# STM32F765BGT6 register map
File version: 1.0
Registers are 32-bit, access not given, reset 0x0 unless marked. A register's access mark holds for its fields unless they carry their own. Offsets are from the block's base; [hi:lo] are bit positions; {n}, {i} and the like mark numbered series; 'fields as' and 'values as' point back to an identical list.

## JPEG
Base 0x50051000
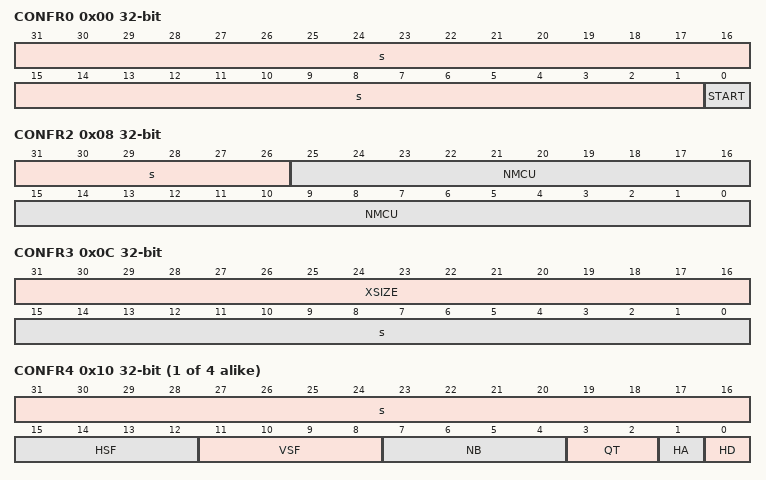
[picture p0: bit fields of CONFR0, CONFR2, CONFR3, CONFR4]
0x00 CONFR0
  [31:1] s, [0] START
0x04 CONFR1
  [31:16] YSIZE, [8] HDR, [7:6] NS, [5:4] COLSPACE, [3] DE, [15:2] s, [1:0] NF
0x08 CONFR2
  [31:26] s, [25:0] NMCU
0x0C CONFR3
  [31:16] XSIZE, [15:0] s
{0x0+4i} CONFR{i} (i=4..7)
  [31:16] s, [15:12] HSF, [11:8] VSF, [7:4] NB, [3:2] QT, [1] HA, [0] HD
0x30 CR
  [14] OFF, [13] IFF, [12] ODMAEN, [11] IDMAEN, [31:6] s, [5] EOCIE, [4] OFNEIE, [3] OFTIE, [2] IFNFIE, [1] IFTIE, [0] JCEN
0x34 SR
  [7] COF, [6] HPDF, [5] EOCF, [4] OFNEF, [3] OFTF, [2] IFNFF, [1] IFTF, [31:0] s
0x38 CFR
  [6] CHPDF, [5] CEOCF, [31:0] s
0x40 DIR
  [31:0] DATAIN
0x44 DOR
  [31:0] DATAOUT

## CRYP
Base 0x50060000
0x00 CR
  [17:16] GCM_CCMPH, [15] CRYPEN, [14] FFLUSH, [9:8] KEYSIZE, [7:6] DATATYPE, [19:3] ALGOMODE, [2] ALGODIR, [31:0] s
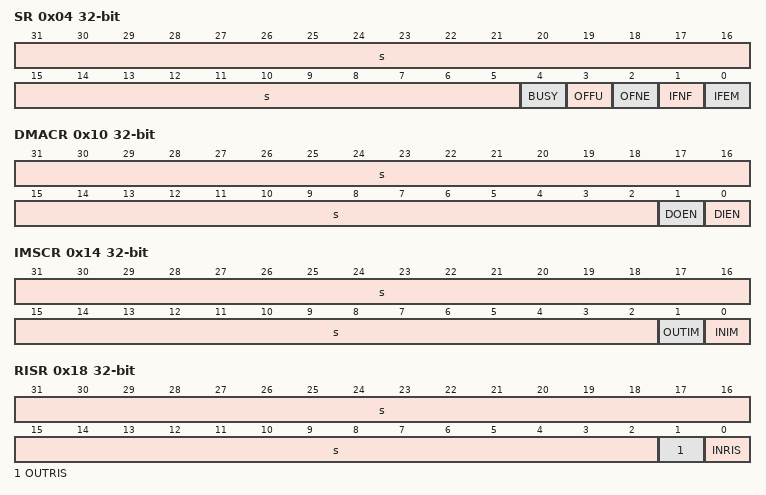
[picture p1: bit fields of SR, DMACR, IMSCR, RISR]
0x04 SR
  [31:5] s, [4] BUSY, [3] OFFU, [2] OFNE, [1] IFNF, [0] IFEM
0x08 DIN
  [31:0] DATAIN
0x0C DOUT
  [31:0] DATAOUT
0x10 DMACR
  [31:2] s, [1] DOEN, [0] DIEN
0x14 IMSCR
  [31:2] s, [1] OUTIM, [0] INIM
0x18 RISR
  [31:2] s, [1] OUTRIS, [0] INRIS
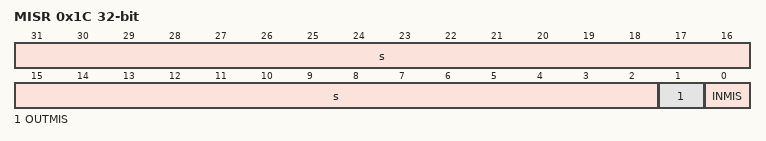
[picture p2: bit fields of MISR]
0x1C MISR
  [31:2] s, [1] OUTMIS, [0] INMIS
0x20 K0LR
  [31:0] CRYP_K0LR
0x24 K0RR
  [31:0] CRYP_K0RR
0x38 K3LR
  [31:0] CRYP_K3LR
0x3C K3RR
  [31:0] CRYP_K3RR
0x40 IV0LR
  [31:0] CRYP_IV0LR
0x44 IV0RR
  [31:0] CRYP_IV0RR
0x48 IV1LR
  [31:0] CRYP_IV1LR
0x4C IV1RR
  [31:0] CRYP_IV1RR

## HASH
Base 0x50060400
0x00 CR
  [16] LKEY, [13] MDMAT, [12] DINNE, [11:8] NBW, [18:7] ALGO, [6] MODE, [5:4] DATATYPE, [3] DMAE, [2] INIT, [31:0] s
0x04 DIN
  [31:0] DATAIN
0x08 STR
  [8] DCAL, [31:5] s, [4:0] NBLW
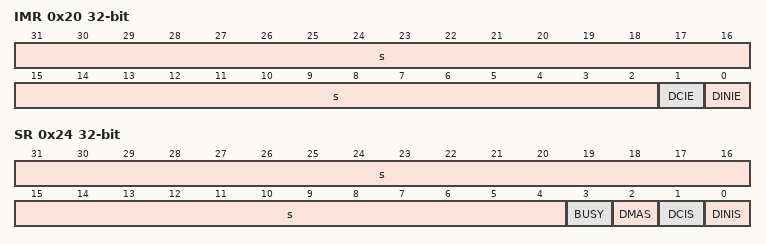
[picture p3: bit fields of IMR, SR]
0x20 IMR
  [31:2] s, [1] DCIE, [0] DINIE
0x24 SR
  [31:4] s, [3] BUSY, [2] DMAS, [1] DCIS, [0] DINIS
0xF8 CSR0
0xFC CSR1
0x1CC CSR53
{0x310+4i} HR{i} (i=0..7)
  [31:0] H{i}

## RNG
Base 0x50060800
0x00 CR
  [5] CED, [3] IE, [2] RNGEN, [31:0] s
0x04 SR
  [6] SEIS, [5] CEIS, [31:3] s, [2] SECS, [1] CECS, [0] DRDY
0x08 DR
  [31:0] RNDATA

## FMC
Base 0xA0000000
0x00 BCR1
  [21] WFDIS, [20] CCLKEN, [19] CBURSTRW, [18:16] CPSIZE, [15] ASYNCWAIT, [14] EXTMOD, [13] WAITEN, [12] WREN, [11] WAITCFG, [9] WAITPOL, [8] BURSTEN, [31:7] s, [6] FACCEN, [5:4] MWID, [3:2] MTYP, [1] MUXEN, [0] MBKEN
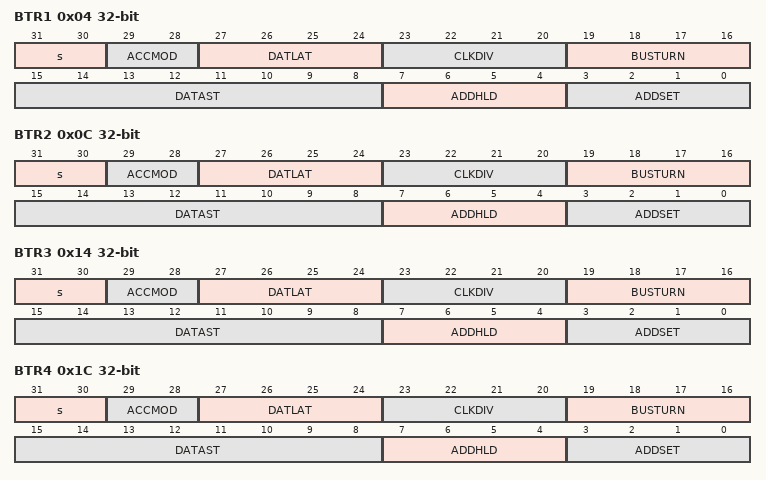
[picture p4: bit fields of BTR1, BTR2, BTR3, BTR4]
0x04 BTR1
  [31:30] s, [29:28] ACCMOD, [27:24] DATLAT, [23:20] CLKDIV, [19:16] BUSTURN, [15:8] DATAST, [7:4] ADDHLD, [3:0] ADDSET
0x08 BCR2
  [19] CBURSTRW, [18:16] CPSIZE, [15] ASYNCWAIT, [14] EXTMOD, [13] WAITEN, [12] WREN, [11] WAITCFG, [9] WAITPOL, [8] BURSTEN, [31:7] s, [6] FACCEN, [5:4] MWID, [3:2] MTYP, [1] MUXEN, [0] MBKEN
0x0C BTR2
  fields as BTR1
0x10 BCR3
  fields as BCR2
0x14 BTR3
  fields as BTR1
0x18 BCR4
  fields as BCR2
0x1C BTR4
  fields as BTR1
0x80 PCR
  [19:17] ECCPS, [16:13] TAR, [12:9] TCLR, [6] ECCEN, [5:4] PWID, [3] PTYP, [2] PBKEN, [1] PWAITEN, [31:0] s
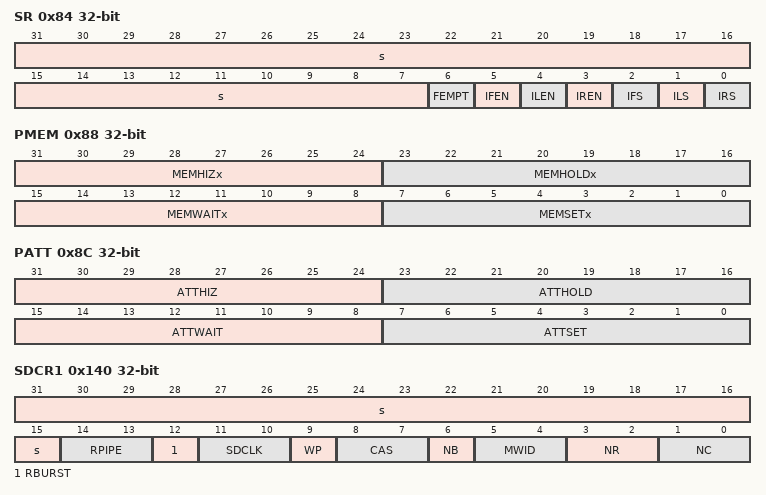
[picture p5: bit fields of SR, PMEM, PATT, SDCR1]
0x84 SR
  [31:7] s, [6] FEMPT, [5] IFEN, [4] ILEN, [3] IREN, [2] IFS, [1] ILS, [0] IRS
0x88 PMEM
  [31:24] MEMHIZx, [23:16] MEMHOLDx, [15:8] MEMWAITx, [7:0] MEMSETx
0x8C PATT
  [31:24] ATTHIZ, [23:16] ATTHOLD, [15:8] ATTWAIT, [7:0] ATTSET
0x94 ECCR
  [31:0] ECCx
{0xFC+8i} BWTR{i} (i=1..4)
  [29:28] ACCMOD, [31:20] s, [19:16] BUSTURN, [15:8] DATAST, [7:4] ADDHLD, [3:0] ADDSET
0x140 SDCR1
  [31:15] s, [14:13] RPIPE, [12] RBURST, [11:10] SDCLK, [9] WP, [8:7] CAS, [6] NB, [5:4] MWID, [3:2] NR, [1:0] NC
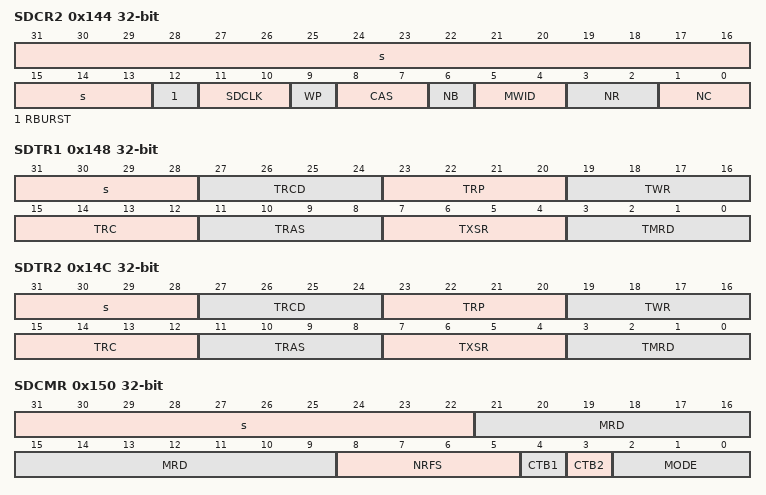
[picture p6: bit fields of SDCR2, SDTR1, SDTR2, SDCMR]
0x144 SDCR2
  [31:13] s, [12] RBURST, [11:10] SDCLK, [9] WP, [8:7] CAS, [6] NB, [5:4] MWID, [3:2] NR, [1:0] NC
0x148 SDTR1
  [31:28] s, [27:24] TRCD, [23:20] TRP, [19:16] TWR, [15:12] TRC, [11:8] TRAS, [7:4] TXSR, [3:0] TMRD
0x14C SDTR2
  fields as SDTR1
0x150 SDCMR
  [31:22] s, [21:9] MRD, [8:5] NRFS, [4] CTB1, [3] CTB2, [2:0] MODE
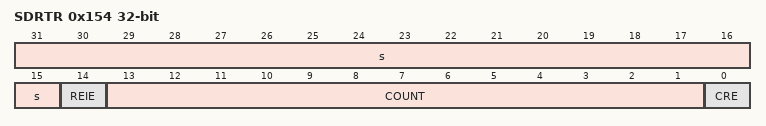
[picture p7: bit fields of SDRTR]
0x154 SDRTR
  [31:15] s, [14] REIE, [13:1] COUNT, [0] CRE
0x158 SDSR
  [5] BUSY, [4:3] MODES2, [2:1] MODES1, [31:0] s

## QUADSPICR
Base 0xA0001000
0x00 CR
  [31:24] PRESCALER, [23] PMM, [22] APMS, [20] TOIE, [19] SMIE, [18] FTIE, [17] TCIE, [16] TEIE, [12:8] FTHRES, [7] FSEL, [6] DFM, [21:5] s, [4] SSHIFT, [3] TCEN, [2] DMAEN, [1] ABORT, [0] EN
0x04 DCR
  [20:16] FSIZE, [10:8] CSHT, [31:1] s, [0] CKMODE
0x08 SR
  [14:8] FLEVEL, [31:6] s, [5] BUS, [4] TOF, [3] SMF, [2] FTF, [1] TCF, [0] TEF
0x0C FCR
  [4] CTOF, [3] CSMF, [31:2] s, [1] CTCF, [0] CTEF
0x10 DLR
  [31:0] DL
0x14 CCR
  [31] DDRM, [30] DHHC, [28] SIOO, [27:26] FMODE, [25:24] DMODE, [29:23] s, [22:18] DCYC, [17:16] ABSIZE, [15:14] ABMODE, [13:12] ADSIZE, [11:10] ADMODE, [9:8] IMODE, [7:0] INSTRUCTION
0x18 AR
  [31:0] ADDRESS
0x1C ABR
  [31:0] ALTERNATE
0x20 DR
  [31:0] DATA
0x24 PSMKR
  [31:0] MASK
0x28 PSMAR
  [31:0] MATCH
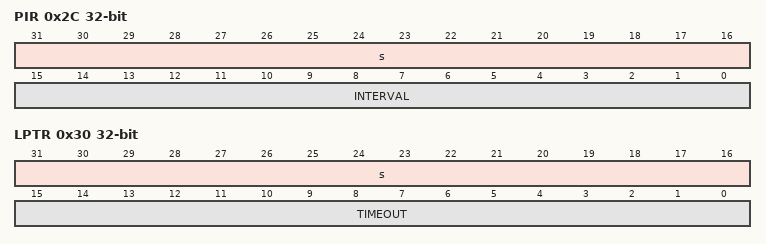
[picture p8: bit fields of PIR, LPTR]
0x2C PIR
  [31:16] s, [15:0] INTERVAL
0x30 LPTR
  [31:16] s, [15:0] TIMEOUT
